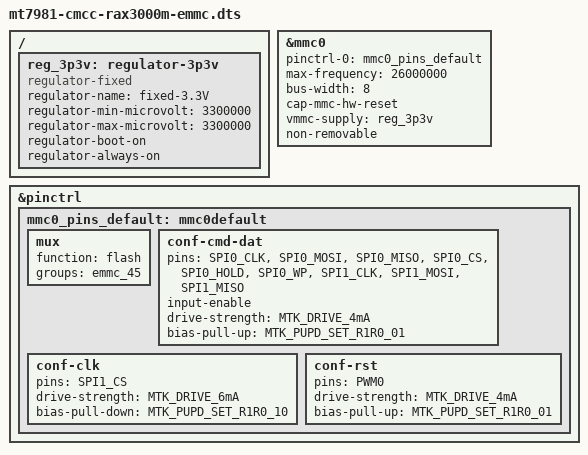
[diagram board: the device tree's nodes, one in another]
// SPDX-License-Identifier: GPL-2.0-only

/dts-v1/;
#include "mt7981-cmcc-rax3000m.dtsi"

/ {
	reg_3p3v: regulator-3p3v {
		compatible = "regulator-fixed";
		regulator-name = "fixed-3.3V";
		regulator-min-microvolt = <3300000>;
		regulator-max-microvolt = <3300000>;
		regulator-boot-on;
		regulator-always-on;
	};
};

&mmc0 {
	pinctrl-names = "default";
	pinctrl-0 = <&mmc0_pins_default>;
	max-frequency = <26000000>;
	bus-width = <8>;
	cap-mmc-hw-reset;
	vmmc-supply = <&reg_3p3v>;
	non-removable;
	status = "okay";
};

&pinctrl {
	mmc0_pins_default: mmc0default {
		mux {
			function = "flash";
			groups =  "emmc_45";
		};
		conf-cmd-dat {
			pins = "SPI0_CLK", "SPI0_MOSI", "SPI0_MISO",
				"SPI0_CS",  "SPI0_HOLD", "SPI0_WP",
				"SPI1_CLK", "SPI1_MOSI", "SPI1_MISO";
			input-enable;
			drive-strength = <MTK_DRIVE_4mA>;
			bias-pull-up = <MTK_PUPD_SET_R1R0_01>;
		};
		conf-clk {
			pins = "SPI1_CS";
			drive-strength = <MTK_DRIVE_6mA>;
			bias-pull-down = <MTK_PUPD_SET_R1R0_10>;
		};
		conf-rst {
			pins = "PWM0";
			drive-strength = <MTK_DRIVE_4mA>;
			bias-pull-up = <MTK_PUPD_SET_R1R0_01>;
		};
	};
};
